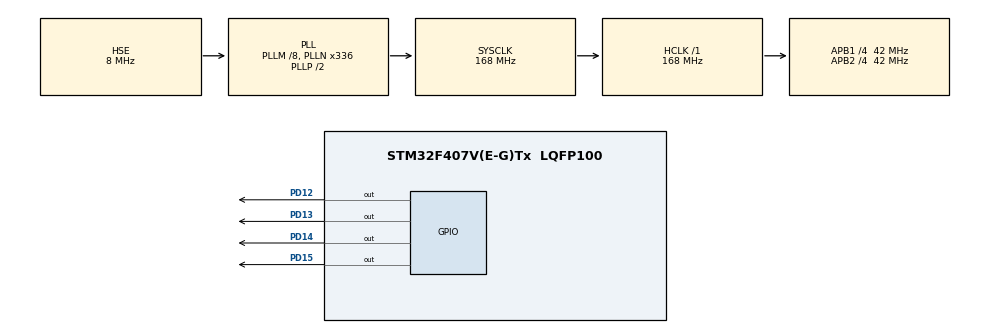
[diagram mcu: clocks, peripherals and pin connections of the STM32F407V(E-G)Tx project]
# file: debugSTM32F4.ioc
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Mcu.Family=STM32F4
Mcu.Name=STM32F407V(E-G)Tx
Mcu.Package=LQFP100
NVIC.PriorityGroup=NVIC_PRIORITYGROUP_4
PA13.Mode=Serial_Wire
PA13.Signal=SYS_JTMS-SWDIO
PA14.Mode=Serial_Wire
PA14.Signal=SYS_JTCK-SWCLK
PD12.GPIO_ModeDefaultOutputPP=GPIO_MODE_OUTPUT_PP
PD12.GPIO_PuPd=GPIO_NOPULL
PD12.GPIO_Speed=GPIO_SPEED_FREQ_VERY_HIGH
PD12.PinState=GPIO_PIN_RESET
PD12.Signal=GPIO_Output
PD13.GPIO_ModeDefaultOutputPP=GPIO_MODE_OUTPUT_PP
PD13.GPIO_PuPd=GPIO_NOPULL
PD13.GPIO_Speed=GPIO_SPEED_FREQ_VERY_HIGH
PD13.PinState=GPIO_PIN_RESET
PD13.Signal=GPIO_Output
PD14.GPIO_ModeDefaultOutputPP=GPIO_MODE_OUTPUT_PP
PD14.GPIO_PuPd=GPIO_NOPULL
PD14.GPIO_Speed=GPIO_SPEED_FREQ_VERY_HIGH
PD14.PinState=GPIO_PIN_RESET
PD14.Signal=GPIO_Output
PD15.GPIO_ModeDefaultOutputPP=GPIO_MODE_OUTPUT_PP
PD15.GPIO_PuPd=GPIO_NOPULL
PD15.GPIO_Speed=GPIO_SPEED_FREQ_VERY_HIGH
PD15.PinState=GPIO_PIN_RESET
PD15.Signal=GPIO_Output
PH0-OSC_IN.Mode=HSE-External-Oscillator
PH0-OSC_IN.Signal=RCC_OSC_IN
PH1-OSC_OUT.Mode=HSE-External-Oscillator
PH1-OSC_OUT.Signal=RCC_OSC_OUT
ProjectManager.HeapSize=0x200
ProjectManager.StackSize=0x400
ProjectManager.TargetToolchain=STM32CubeIDE
RCC.48MHZClocksFreq_Value=84000000
RCC.AHBFreq_Value=168000000
RCC.APB1CLKDivider=RCC_HCLK_DIV4
RCC.APB1Freq_Value=42000000
RCC.APB1TimFreq_Value=84000000
RCC.APB2CLKDivider=RCC_HCLK_DIV4
RCC.APB2Freq_Value=42000000
RCC.APB2TimFreq_Value=84000000
RCC.CortexFreq_Value=168000000
RCC.HCLKFreq_Value=168000000
RCC.HSE_VALUE=8000000
RCC.HSI_VALUE=16000000
RCC.LSE_VALUE=32768
RCC.PLLM=8
RCC.PLLN=336
RCC.PLLSourceVirtual=RCC_PLLSOURCE_HSE
RCC.SYSCLKFreq_VALUE=168000000
RCC.SYSCLKSource=RCC_SYSCLKSOURCE_PLLCLK
RCC.VCOOutputFreq_Value=336000000
board=custom

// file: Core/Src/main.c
/* USER CODE BEGIN Header */
/**
  ******************************************************************************
  * @file           : main.c
  * @brief          : Main program body
  ******************************************************************************
  * @attention
  *
  * Copyright (c) 2023 STMicroelectronics.
  * All rights reserved.
  *
  * This software is licensed under terms that can be found in the LICENSE file
  * in the root directory of this software component.
  * If no LICENSE file comes with this software, it is provided AS-IS.
  *
  ******************************************************************************
  */
/* USER CODE END Header */
#include <stdio.h>
#include <stdint.h>
#include "main.h"

void SystemClock_Config(void);
static void MX_GPIO_Init(void);

/* USER CODE BEGIN 0 */
float m = 1.0;
#define TOP0        3599.0
uint32_t i = 0;
int _write(int file, char *ptr, int len){
  /* Implement your write code here, this is used by puts and printf for example */
  int i=0;
  for(i=0 ; i<len ; i++)
    ITM_SendChar((*ptr++));
  return len;
}
uint32_t s1, s2, s3;
float va[201] = {0.5000, 0.5302, 0.5604, 0.5905, 0.6205, 0.6355, 0.6652, 0.6948, 0.7241, 0.7532, 0.7676, 0.7962, 0.8244, 0.8522, 0.8796, 0.8932, 0.9199, 0.9373, 0.9455, 0.9532, 0.9568, 0.9636, 0.9698, 0.9755, 0.9806, 0.9830, 0.9872, 0.9908, 0.9938, 0.9963, 0.9981, 0.9988, 0.9997, 1.0000, 0.9997, 0.9988, 0.9981, 0.9963, 0.9938, 0.9908, 0.9872, 0.9851, 0.9806, 0.9755, 0.9698, 0.9668, 0.9603, 0.9532, 0.9455, 0.9373, 0.9330, 0.9415, 0.9494, 0.9568, 0.9636, 0.9668, 0.9728, 0.9782, 0.9830, 0.9872, 0.9891, 0.9924, 0.9951, 0.9973, 0.9988, 0.9993, 0.9999, 0.9999, 0.9993, 0.9981, 0.9973, 0.9951, 0.9924, 0.9891, 0.9851, 0.9830, 0.9782, 0.9728, 0.9668, 0.9603, 0.9568, 0.9494, 0.9415, 0.9330, 0.9066, 0.8932, 0.8660, 0.8384, 0.8104, 0.7820, 0.7676, 0.7387, 0.7095, 0.6801, 0.6504, 0.6355, 0.6055, 0.5755, 0.5453, 0.5151, 0.5000, 0.4698, 0.4396, 0.4095, 0.3795, 0.3645, 0.3348, 0.3052, 0.2759, 0.2468, 0.2324, 0.2038, 0.1756, 0.1478, 0.1204, 0.1068, 0.0801, 0.0627, 0.0545, 0.0468, 0.0432, 0.0364, 0.0302, 0.0245, 0.0194, 0.0170, 0.0128, 0.0092, 0.0062, 0.0037, 0.0027, 0.0012, 0.0003, 0.0000, 0.0003, 0.0007, 0.0019, 0.0037, 0.0062, 0.0092, 0.0109, 0.0149, 0.0194, 0.0245, 0.0302, 0.0332, 0.0397, 0.0468, 0.0545, 0.0627, 0.0670, 0.0585, 0.0506, 0.0432, 0.0364, 0.0332, 0.0272, 0.0218, 0.0170, 0.0128, 0.0109, 0.0076, 0.0049, 0.0027, 0.0012, 0.0007, 0.0001, 0.0001, 0.0007, 0.0019, 0.0027, 0.0049, 0.0076, 0.0109, 0.0149, 0.0170, 0.0218, 0.0272, 0.0332, 0.0397, 0.0432, 0.0506, 0.0585, 0.0670, 0.0934, 0.1068, 0.1340, 0.1616, 0.1896, 0.2180, 0.2324, 0.2613, 0.2905, 0.3199, 0.3496, 0.3645, 0.3945, 0.4245, 0.4547, 0.4849};
float vb[201] = {1.0000, 0.9997, 0.9988, 0.9973, 0.9951, 0.9938, 0.9908, 0.9872, 0.9830, 0.9782, 0.9755, 0.9698, 0.9636, 0.9568, 0.9494, 0.9455, 0.9373, 0.9199, 0.8932, 0.8660, 0.8522, 0.8244, 0.7962, 0.7676, 0.7387, 0.7241, 0.6948, 0.6652, 0.6355, 0.6055, 0.5755, 0.5604, 0.5302, 0.5000, 0.4698, 0.4396, 0.4245, 0.3945, 0.3645, 0.3348, 0.3052, 0.2905, 0.2613, 0.2324, 0.2038, 0.1896, 0.1616, 0.1340, 0.1068, 0.0801, 0.0670, 0.0585, 0.0506, 0.0432, 0.0364, 0.0332, 0.0272, 0.0218, 0.0170, 0.0128, 0.0109, 0.0076, 0.0049, 0.0027, 0.0012, 0.0007, 0.0001, 0.0001, 0.0007, 0.0019, 0.0027, 0.0049, 0.0076, 0.0109, 0.0149, 0.0170, 0.0218, 0.0272, 0.0332, 0.0397, 0.0432, 0.0506, 0.0585, 0.0670, 0.0585, 0.0545, 0.0468, 0.0397, 0.0332, 0.0272, 0.0245, 0.0194, 0.0149, 0.0109, 0.0076, 0.0062, 0.0037, 0.0019, 0.0007, 0.0001, 0.0000, 0.0003, 0.0012, 0.0027, 0.0049, 0.0062, 0.0092, 0.0128, 0.0170, 0.0218, 0.0245, 0.0302, 0.0364, 0.0432, 0.0506, 0.0545, 0.0627, 0.0801, 0.1068, 0.1340, 0.1478, 0.1756, 0.2038, 0.2324, 0.2613, 0.2759, 0.3052, 0.3348, 0.3645, 0.3945, 0.4095, 0.4396, 0.4698, 0.5000, 0.5302, 0.5453, 0.5755, 0.6055, 0.6355, 0.6652, 0.6801, 0.7095, 0.7387, 0.7676, 0.7962, 0.8104, 0.8384, 0.8660, 0.8932, 0.9199, 0.9330, 0.9415, 0.9494, 0.9568, 0.9636, 0.9668, 0.9728, 0.9782, 0.9830, 0.9872, 0.9891, 0.9924, 0.9951, 0.9973, 0.9988, 0.9993, 0.9999, 0.9999, 0.9993, 0.9981, 0.9973, 0.9951, 0.9924, 0.9891, 0.9851, 0.9830, 0.9782, 0.9728, 0.9668, 0.9603, 0.9568, 0.9494, 0.9415, 0.9330, 0.9415, 0.9455, 0.9532, 0.9603, 0.9668, 0.9728, 0.9755, 0.9806, 0.9851, 0.9891, 0.9924, 0.9938, 0.9963, 0.9981, 0.9993, 0.9999};
float vc[201] = {0.0000, 0.0003, 0.0012, 0.0027, 0.0049, 0.0062, 0.0092, 0.0128, 0.0170, 0.0218, 0.0245, 0.0302, 0.0364, 0.0432, 0.0506, 0.0545, 0.0627, 0.0627, 0.0545, 0.0468, 0.0432, 0.0364, 0.0302, 0.0245, 0.0194, 0.0170, 0.0128, 0.0092, 0.0062, 0.0037, 0.0019, 0.0012, 0.0003, 0.0000, 0.0003, 0.0012, 0.0019, 0.0037, 0.0062, 0.0092, 0.0128, 0.0149, 0.0194, 0.0245, 0.0302, 0.0332, 0.0397, 0.0468, 0.0545, 0.0627, 0.0670, 0.0934, 0.1204, 0.1478, 0.1756, 0.1896, 0.2180, 0.2468, 0.2759, 0.3052, 0.3199, 0.3496, 0.3795, 0.4095, 0.4396, 0.4547, 0.4849, 0.5151, 0.5453, 0.5755, 0.5905, 0.6205, 0.6504, 0.6801, 0.7095, 0.7241, 0.7532, 0.7820, 0.8104, 0.8384, 0.8522, 0.8796, 0.9066, 0.9330, 0.9415, 0.9455, 0.9532, 0.9603, 0.9668, 0.9728, 0.9755, 0.9806, 0.9851, 0.9891, 0.9924, 0.9938, 0.9963, 0.9981, 0.9993, 0.9999, 1.0000, 0.9997, 0.9988, 0.9973, 0.9951, 0.9938, 0.9908, 0.9872, 0.9830, 0.9782, 0.9755, 0.9698, 0.9636, 0.9568, 0.9494, 0.9455, 0.9373, 0.9373, 0.9455, 0.9532, 0.9568, 0.9636, 0.9698, 0.9755, 0.9806, 0.9830, 0.9872, 0.9908, 0.9938, 0.9963, 0.9973, 0.9988, 0.9997, 1.0000, 0.9997, 0.9993, 0.9981, 0.9963, 0.9938, 0.9908, 0.9891, 0.9851, 0.9806, 0.9755, 0.9698, 0.9668, 0.9603, 0.9532, 0.9455, 0.9373, 0.9330, 0.9066, 0.8796, 0.8522, 0.8244, 0.8104, 0.7820, 0.7532, 0.7241, 0.6948, 0.6801, 0.6504, 0.6205, 0.5905, 0.5604, 0.5453, 0.5151, 0.4849, 0.4547, 0.4245, 0.4095, 0.3795, 0.3496, 0.3199, 0.2905, 0.2759, 0.2468, 0.2180, 0.1896, 0.1616, 0.1478, 0.1204, 0.0934, 0.0670, 0.0585, 0.0545, 0.0468, 0.0397, 0.0332, 0.0272, 0.0245, 0.0194, 0.0149, 0.0109, 0.0076, 0.0062, 0.0037, 0.0019, 0.0007, 0.0001};

/* USER CODE END 0 */

int main(void)
{

  /* MCU Configuration--------------------------------------------------------*/

  /* Reset of all peripherals, Initializes the Flash interface and the Systick. */
  HAL_Init();

  /* Configure the system clock */
  SystemClock_Config();

  /* Initialize all configured peripherals */
  MX_GPIO_Init();

  /* Infinite loop */
  while (1)
  {
//	  HAL_GPIO_TogglePin(GPIOD, GPIO_PIN_12 | GPIO_PIN_13 | GPIO_PIN_14 | GPIO_PIN_15);
//	  HAL_Delay(1000);
//	  printf("counter i = %ld\n", i);
	    s1 = ((va[i] - 0.5) * m + 0.5) * TOP0 + 0.5;           // PWM Pin A0
	    s2 = ((vb[i] - 0.5) * m + 0.5) * TOP0 + 0.5;           // PWM Pin A1
	    s3 = ((vc[i] - 0.5) * m + 0.5) * TOP0 + 0.5;           // PWM Pin A2

	  i++;
	  if (i >= 200) i = 0;
	  HAL_Delay(50);
  }
}

void SystemClock_Config(void)
{
  RCC_OscInitTypeDef RCC_OscInitStruct = {0};
  RCC_ClkInitTypeDef RCC_ClkInitStruct = {0};

  /** Configure the main internal regulator output voltage
  */
  __HAL_RCC_PWR_CLK_ENABLE();
  __HAL_PWR_VOLTAGESCALING_CONFIG(PWR_REGULATOR_VOLTAGE_SCALE1);

  /** Initializes the RCC Oscillators according to the specified parameters
  * in the RCC_OscInitTypeDef structure.
  */
  RCC_OscInitStruct.OscillatorType = RCC_OSCILLATORTYPE_HSE;
  RCC_OscInitStruct.HSEState = RCC_HSE_ON;
  RCC_OscInitStruct.PLL.PLLState = RCC_PLL_ON;
  RCC_OscInitStruct.PLL.PLLSource = RCC_PLLSOURCE_HSE;
  RCC_OscInitStruct.PLL.PLLM = 8;
  RCC_OscInitStruct.PLL.PLLN = 336;
  RCC_OscInitStruct.PLL.PLLP = RCC_PLLP_DIV2;
  RCC_OscInitStruct.PLL.PLLQ = 4;
  if (HAL_RCC_OscConfig(&RCC_OscInitStruct) != HAL_OK)
  {
    Error_Handler();
  }

  /** Initializes the CPU, AHB and APB buses clocks
  */
  RCC_ClkInitStruct.ClockType = RCC_CLOCKTYPE_HCLK|RCC_CLOCKTYPE_SYSCLK
                              |RCC_CLOCKTYPE_PCLK1|RCC_CLOCKTYPE_PCLK2;
  RCC_ClkInitStruct.SYSCLKSource = RCC_SYSCLKSOURCE_PLLCLK;
  RCC_ClkInitStruct.AHBCLKDivider = RCC_SYSCLK_DIV1;
  RCC_ClkInitStruct.APB1CLKDivider = RCC_HCLK_DIV4;
  RCC_ClkInitStruct.APB2CLKDivider = RCC_HCLK_DIV4;

  if (HAL_RCC_ClockConfig(&RCC_ClkInitStruct, FLASH_LATENCY_5) != HAL_OK)
  {
    Error_Handler();
  }
}

static void MX_GPIO_Init(void)
{
  GPIO_InitTypeDef GPIO_InitStruct = {0};

  /* GPIO Ports Clock Enable */
  __HAL_RCC_GPIOH_CLK_ENABLE();
  __HAL_RCC_GPIOD_CLK_ENABLE();
  __HAL_RCC_GPIOA_CLK_ENABLE();

  /*Configure GPIO pin Output Level */
  HAL_GPIO_WritePin(GPIOD, GPIO_PIN_12|GPIO_PIN_13|GPIO_PIN_14|GPIO_PIN_15, GPIO_PIN_RESET);

  /*Configure GPIO pins : PD12 PD13 PD14 PD15 */
  GPIO_InitStruct.Pin = GPIO_PIN_12|GPIO_PIN_13|GPIO_PIN_14|GPIO_PIN_15;
  GPIO_InitStruct.Mode = GPIO_MODE_OUTPUT_PP;
  GPIO_InitStruct.Pull = GPIO_NOPULL;
  GPIO_InitStruct.Speed = GPIO_SPEED_FREQ_VERY_HIGH;
  HAL_GPIO_Init(GPIOD, &GPIO_InitStruct);

}

void Error_Handler(void)
{
  __disable_irq();
  while (1)
  {
  }
}
